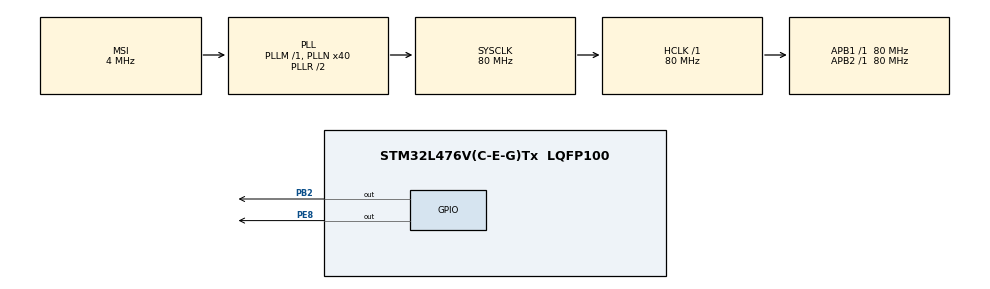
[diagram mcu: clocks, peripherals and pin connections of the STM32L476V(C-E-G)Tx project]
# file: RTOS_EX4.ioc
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FREERTOS.Tasks01=defaultTask,0,128,StartDefaultTask,Default,NULL
Mcu.Family=STM32L4
Mcu.Name=STM32L476V(C-E-G)Tx
Mcu.Package=LQFP100
NVIC.PriorityGroup=NVIC_PRIORITYGROUP_4
NVIC.TIM6_DAC_IRQn=true\:0\:0\:false\:false\:true\:false\:false\:true
NVIC.TimeBase=TIM6_DAC_IRQn
NVIC.TimeBaseIP=TIM6
PB2.Signal=GPIO_Output
PE8.Signal=GPIO_Output
ProjectManager.HeapSize=0x200
ProjectManager.StackSize=0x400
ProjectManager.TargetToolchain=EWARM V8
RCC.AHBFreq_Value=80000000
RCC.APB1Freq_Value=80000000
RCC.APB1TimFreq_Value=80000000
RCC.APB2Freq_Value=80000000
RCC.APB2TimFreq_Value=80000000
RCC.CortexFreq_Value=80000000
RCC.HCLKFreq_Value=80000000
RCC.HSE_VALUE=8000000
RCC.HSI_VALUE=16000000
RCC.LSE_VALUE=32768
RCC.MSI_VALUE=4000000
RCC.PLLN=40
RCC.SYSCLKFreq_VALUE=80000000
RCC.SYSCLKSource=RCC_SYSCLKSOURCE_PLLCLK
RCC.VCOOutputFreq_Value=160000000
VP_FREERTOS_VS_CMSIS_V1.Mode=CMSIS_V1
VP_SYS_VS_tim6.Mode=TIM6
board=custom

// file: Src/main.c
/* USER CODE BEGIN Header */
/**
  ******************************************************************************
  * @file           : main.c
  * @brief          : Main program body
  ******************************************************************************
  * @attention
  *
  * <h2><center>&copy; Copyright (c) 2019 STMicroelectronics.
  * All rights reserved.</center></h2>
  *
  * This software component is licensed by ST under BSD 3-Clause license,
  * the "License"; You may not use this file except in compliance with the
  * License. You may obtain a copy of the License at:
  *                        opensource.org/licenses/BSD-3-Clause
  *
  ******************************************************************************
  */
/* USER CODE END Header */

#include "main.h"

/* USER CODE BEGIN PV */
TaskHandle_t xProducerHandle = NULL;
TaskHandle_t xConsumerHandle = NULL;
SemaphoreHandle_t xSemaphore = NULL;
/* USER CODE END PV */

void SystemClock_Config(void);
static void MX_GPIO_Init(void);

/* USER CODE BEGIN PFP */
static void vProducerTask(void *pvParameters);
static void vConsumerTask(void *pvParameters);
/* USER CODE END PFP */

int main(void)
{

  /* MCU Configuration--------------------------------------------------------*/

  /* Reset of all peripherals, Initializes the Flash interface and the Systick. */
  HAL_Init();

  /* Configure the system clock */
  SystemClock_Config();

  /* Initialize all configured peripherals */
  MX_GPIO_Init();

  /* USER CODE BEGIN RTOS_MUTEX */
  xSemaphore = xSemaphoreCreateMutex();
  /* USER CODE END RTOS_MUTEX */

  /* USER CODE BEGIN RTOS_THREADS */
  xTaskCreate(vProducerTask, "Producer", 128, NULL, osPriorityNormal, &xProducerHandle);
  xTaskCreate(vConsumerTask, "Consumer", 128, NULL, osPriorityNormal, &xConsumerHandle);
  /* USER CODE END RTOS_THREADS */

  /* Start scheduler */
  vTaskStartScheduler();

  /* We should never get here as control is now taken by the scheduler */

  /* Infinite loop */
  /* USER CODE BEGIN WHILE */
  while (1)
  {
    printf("Running in main\n");
    HAL_Delay(1000);
    /* USER CODE END WHILE */

  }
}

void SystemClock_Config(void)
{
  RCC_OscInitTypeDef RCC_OscInitStruct = {0};
  RCC_ClkInitTypeDef RCC_ClkInitStruct = {0};

  /** Initializes the CPU, AHB and APB busses clocks
  */
  RCC_OscInitStruct.OscillatorType = RCC_OSCILLATORTYPE_MSI;
  RCC_OscInitStruct.MSIState = RCC_MSI_ON;
  RCC_OscInitStruct.MSICalibrationValue = 0;
  RCC_OscInitStruct.MSIClockRange = RCC_MSIRANGE_6;
  RCC_OscInitStruct.PLL.PLLState = RCC_PLL_ON;
  RCC_OscInitStruct.PLL.PLLSource = RCC_PLLSOURCE_MSI;
  RCC_OscInitStruct.PLL.PLLM = 1;
  RCC_OscInitStruct.PLL.PLLN = 40;
  RCC_OscInitStruct.PLL.PLLP = RCC_PLLP_DIV7;
  RCC_OscInitStruct.PLL.PLLQ = RCC_PLLQ_DIV2;
  RCC_OscInitStruct.PLL.PLLR = RCC_PLLR_DIV2;
  if (HAL_RCC_OscConfig(&RCC_OscInitStruct) != HAL_OK)
  {
    Error_Handler();
  }
  /** Initializes the CPU, AHB and APB busses clocks
  */
  RCC_ClkInitStruct.ClockType = RCC_CLOCKTYPE_HCLK|RCC_CLOCKTYPE_SYSCLK
                              |RCC_CLOCKTYPE_PCLK1|RCC_CLOCKTYPE_PCLK2;
  RCC_ClkInitStruct.SYSCLKSource = RCC_SYSCLKSOURCE_PLLCLK;
  RCC_ClkInitStruct.AHBCLKDivider = RCC_SYSCLK_DIV1;
  RCC_ClkInitStruct.APB1CLKDivider = RCC_HCLK_DIV1;
  RCC_ClkInitStruct.APB2CLKDivider = RCC_HCLK_DIV1;

  if (HAL_RCC_ClockConfig(&RCC_ClkInitStruct, FLASH_LATENCY_4) != HAL_OK)
  {
    Error_Handler();
  }
  /** Configure the main internal regulator output voltage
  */
  if (HAL_PWREx_ControlVoltageScaling(PWR_REGULATOR_VOLTAGE_SCALE1) != HAL_OK)
  {
    Error_Handler();
  }
}

static void MX_GPIO_Init(void)
{
  GPIO_InitTypeDef GPIO_InitStruct = {0};

  /* GPIO Ports Clock Enable */
  __HAL_RCC_GPIOB_CLK_ENABLE();
  __HAL_RCC_GPIOE_CLK_ENABLE();

  /*Configure GPIO pin Output Level */
  HAL_GPIO_WritePin(GPIOB, GPIO_PIN_2, GPIO_PIN_RESET);

  /*Configure GPIO pin Output Level */
  HAL_GPIO_WritePin(GPIOE, GPIO_PIN_8, GPIO_PIN_RESET);

  /*Configure GPIO pin : PB2 */
  GPIO_InitStruct.Pin = GPIO_PIN_2;
  GPIO_InitStruct.Mode = GPIO_MODE_OUTPUT_PP;
  GPIO_InitStruct.Pull = GPIO_NOPULL;
  GPIO_InitStruct.Speed = GPIO_SPEED_FREQ_LOW;
  HAL_GPIO_Init(GPIOB, &GPIO_InitStruct);

  /*Configure GPIO pin : PE8 */
  GPIO_InitStruct.Pin = GPIO_PIN_8;
  GPIO_InitStruct.Mode = GPIO_MODE_OUTPUT_PP;
  GPIO_InitStruct.Pull = GPIO_NOPULL;
  GPIO_InitStruct.Speed = GPIO_SPEED_FREQ_LOW;
  HAL_GPIO_Init(GPIOE, &GPIO_InitStruct);

}

/* USER CODE BEGIN 4 */
void vProducerTask(void *pvParameters)
{
  const TickType_t xDelayInMs = pdMS_TO_TICKS(1000);
  const TickType_t xTicksToWait = pdMS_TO_TICKS(10);

  for(;;)
  {
    if(xSemaphoreTake(xSemaphore, xTicksToWait) == pdPASS)
    {
      /* We were able to obtain the semaphore and can now access the shared resource. */
      HAL_GPIO_WritePin(GPIOE, GPIO_PIN_8, GPIO_PIN_SET);
      vTaskDelay(xDelayInMs);
      // HAL_GPIO_WritePin(GPIOB, GPIO_PIN_2, GPIO_PIN_SET);
      /* We have finished accessing the shared resource.  Release the semaphore. */
      xSemaphoreGive(xSemaphore);
    }
    else
    {
      /* We could not obtain the semaphore and can therefore not access the shared resource safely. */
    }
    vTaskDelay(xDelayInMs);
  }
}

void vConsumerTask(void *pvParameters)
{
  const TickType_t xDelayInMs = pdMS_TO_TICKS(500);
  const TickType_t xTicksToWait = pdMS_TO_TICKS(10);

  for(;;)
  {
    if(xSemaphoreTake(xSemaphore, xTicksToWait) == pdTRUE)
    {
      /* We were able to obtain the semaphore and can now access the shared resource. */
      HAL_GPIO_WritePin(GPIOE, GPIO_PIN_8, GPIO_PIN_RESET);
      vTaskDelay(xDelayInMs);
      // HAL_GPIO_WritePin(GPIOB, GPIO_PIN_2, GPIO_PIN_RESET);
      /* We have finished accessing the shared resource.  Release the semaphore. */
      xSemaphoreGive(xSemaphore);
    }
    else
    {
      /* We could not obtain the semaphore and can therefore not access the shared resource safely. */
    }
    vTaskDelay(xDelayInMs);
  }
}
/* USER CODE END 4 */

void HAL_TIM_PeriodElapsedCallback(TIM_HandleTypeDef *htim)
{
  if (htim->Instance == TIM6) {
    HAL_IncTick();
  }
}

void Error_Handler(void)
{
  /* USER CODE BEGIN Error_Handler_Debug */
  /* User can add his own implementation to report the HAL error return state */
  printf("Error Handler\r\n");
  while (1);
  /* USER CODE END Error_Handler_Debug */
}

/************************ (C) COPYRIGHT STMicroelectronics *****END OF FILE****/
